VERSION "SYNTHETIC extension for rivian_r1t: quantities the open-source database of this vehicle does not publish. NOT the manufacturer's data."

NS_ :

BS_:

BU_: EXT

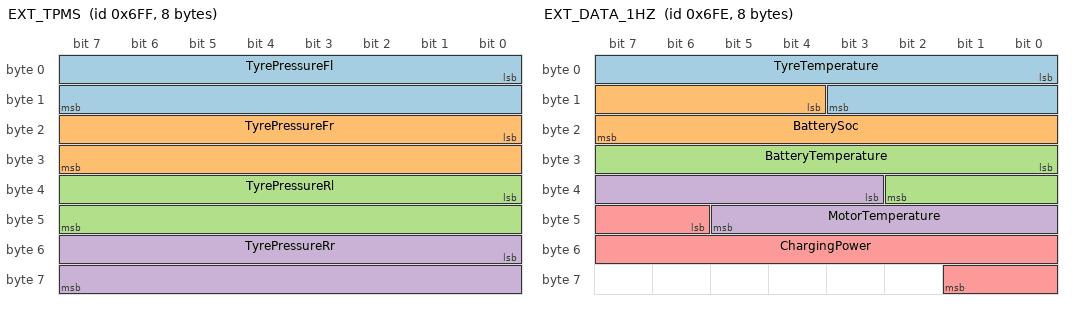
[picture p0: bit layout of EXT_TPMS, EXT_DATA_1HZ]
BO_ 1791 EXT_TPMS: 8 EXT
 SG_ TyrePressureFl : 0|16@1+ (0.1,0) [0|600] "kPa" Vector__XXX
 SG_ TyrePressureFr : 16|16@1+ (0.1,0) [0|600] "kPa" Vector__XXX
 SG_ TyrePressureRl : 32|16@1+ (0.1,0) [0|600] "kPa" Vector__XXX
 SG_ TyrePressureRr : 48|16@1+ (0.1,0) [0|600] "kPa" Vector__XXX

BO_ 1790 EXT_DATA_1HZ: 8 EXT
 SG_ TyreTemperature : 0|12@1+ (0.1,-40) [-40|120] "C" Vector__XXX
 SG_ BatterySoc : 12|12@1+ (0.1,0) [0|100] "%" Vector__XXX
 SG_ BatteryTemperature : 24|11@1+ (0.1,-40) [-40|90] "C" Vector__XXX
 SG_ MotorTemperature : 35|11@1+ (0.1,-40) [-40|200] "C" Vector__XXX
 SG_ ChargingPower : 46|12@1+ (0.1,0) [0|300] "kW" Vector__XXX

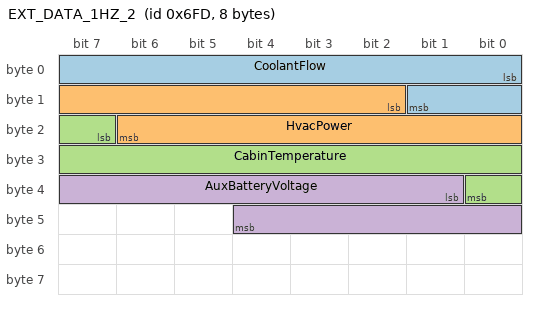
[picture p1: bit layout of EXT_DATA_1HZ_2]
BO_ 1789 EXT_DATA_1HZ_2: 8 EXT
 SG_ CoolantFlow : 0|10@1+ (0.1,0) [0|60] "L/min" Vector__XXX
 SG_ HvacPower : 10|13@1+ (1,0) [0|8000] "W" Vector__XXX
 SG_ CabinTemperature : 23|10@1+ (0.1,-20) [-20|80] "C" Vector__XXX
 SG_ AuxBatteryVoltage : 33|12@1+ (0.01,0) [6|16] "V" Vector__XXX

BO_ 1788 EXT_DATA_5HZ: 8 EXT
 SG_ BatteryVoltage : 0|14@1+ (0.05,0) [0|800] "V" Vector__XXX
 SG_ BatteryCurrent : 14|16@1- (0.1,0) [-900|900] "A" Vector__XXX

BO_ 1787 EXT_DATA_0_2HZ: 8 EXT
 SG_ ReportedRange : 0|12@1+ (1,0) [0|1500] "km" Vector__XXX

BO_ 1786 EXT_DATA_10HZ: 8 EXT
 SG_ MotorTorque : 0|14@1- (0.1,0) [-500|500] "Nm" Vector__XXX

BO_ 1785 EXT_KEYSTATE: 8 EXT
 SG_ ChargingActive : 0|1@1+ (1,0) [0|1] "" Vector__XXX
 SG_ Ignition : 1|1@1+ (1,0) [0|1] "" Vector__XXX
